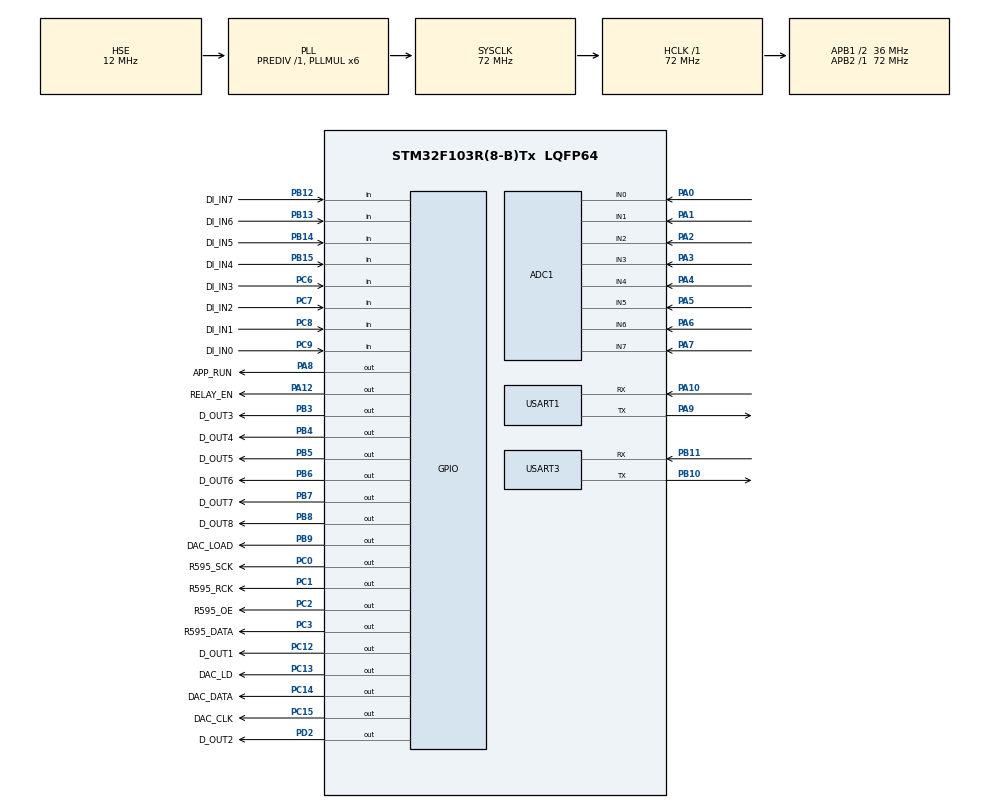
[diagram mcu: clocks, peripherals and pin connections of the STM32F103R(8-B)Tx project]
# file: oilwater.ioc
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ADC1.Channel-0\#ChannelRegularConversion=ADC_CHANNEL_0
ADC1.Channel-1\#ChannelRegularConversion=ADC_CHANNEL_1
ADC1.Channel-2\#ChannelRegularConversion=ADC_CHANNEL_2
ADC1.Channel-3\#ChannelRegularConversion=ADC_CHANNEL_3
ADC1.Channel-4\#ChannelRegularConversion=ADC_CHANNEL_4
ADC1.Channel-5\#ChannelRegularConversion=ADC_CHANNEL_5
ADC1.Channel-6\#ChannelRegularConversion=ADC_CHANNEL_6
ADC1.Channel-7\#ChannelRegularConversion=ADC_CHANNEL_7
ADC1.ContinuousConvMode=ENABLE
ADC1.DiscontinuousConvMode=DISABLE
ADC1.ExternalTrigConv=ADC_SOFTWARE_START
ADC1.NbrOfConversion=8
ADC1.NbrOfConversionFlag=1
ADC1.Rank-0\#ChannelRegularConversion=1
ADC1.Rank-1\#ChannelRegularConversion=2
ADC1.Rank-2\#ChannelRegularConversion=3
ADC1.Rank-3\#ChannelRegularConversion=4
ADC1.Rank-4\#ChannelRegularConversion=5
ADC1.Rank-5\#ChannelRegularConversion=6
ADC1.Rank-6\#ChannelRegularConversion=7
ADC1.Rank-7\#ChannelRegularConversion=8
ADC1.SamplingTime-0\#ChannelRegularConversion=ADC_SAMPLETIME_1CYCLE_5
ADC1.SamplingTime-1\#ChannelRegularConversion=ADC_SAMPLETIME_1CYCLE_5
ADC1.SamplingTime-2\#ChannelRegularConversion=ADC_SAMPLETIME_1CYCLE_5
ADC1.SamplingTime-3\#ChannelRegularConversion=ADC_SAMPLETIME_1CYCLE_5
ADC1.SamplingTime-4\#ChannelRegularConversion=ADC_SAMPLETIME_1CYCLE_5
ADC1.SamplingTime-5\#ChannelRegularConversion=ADC_SAMPLETIME_1CYCLE_5
ADC1.SamplingTime-6\#ChannelRegularConversion=ADC_SAMPLETIME_1CYCLE_5
ADC1.SamplingTime-7\#ChannelRegularConversion=ADC_SAMPLETIME_1CYCLE_5
ADC1.master=1
Dma.ADC1.0.Direction=DMA_PERIPH_TO_MEMORY
Dma.ADC1.0.Instance=DMA1_Channel1
Dma.ADC1.0.MemDataAlignment=DMA_MDATAALIGN_HALFWORD
Dma.ADC1.0.MemInc=DMA_MINC_ENABLE
Dma.ADC1.0.Mode=DMA_CIRCULAR
Dma.ADC1.0.PeriphDataAlignment=DMA_PDATAALIGN_HALFWORD
Dma.ADC1.0.PeriphInc=DMA_PINC_DISABLE
Dma.ADC1.0.Priority=DMA_PRIORITY_LOW
Dma.Request0=ADC1
Mcu.Family=STM32F1
Mcu.Name=STM32F103R(8-B)Tx
Mcu.Package=LQFP64
NVIC.ADC1_2_IRQn=true\:0\:0\:false\:false\:true\:true\:true
NVIC.DMA1_Channel1_IRQn=true\:0\:0\:false\:false\:true\:false\:true
NVIC.PriorityGroup=NVIC_PRIORITYGROUP_4
NVIC.USART1_IRQn=true\:0\:0\:false\:false\:true\:true\:true
NVIC.USART3_IRQn=true\:0\:0\:false\:false\:true\:true\:true
NVIC.WWDG_IRQn=true\:0\:0\:false\:false\:true\:true\:true
PA0-WKUP.Signal=ADCx_IN0
PA1.Signal=ADCx_IN1
PA10.Mode=Asynchronous
PA10.Signal=USART1_RX
PA12.GPIO_Label=RELAY_EN
PA12.Signal=GPIO_Output
PA13.Mode=Serial_Wire
PA13.Signal=SYS_JTMS-SWDIO
PA14.Mode=Serial_Wire
PA14.Signal=SYS_JTCK-SWCLK
PA2.Signal=ADCx_IN2
PA3.Signal=ADCx_IN3
PA4.Signal=ADCx_IN4
PA5.Signal=ADCx_IN5
PA6.Signal=ADCx_IN6
PA7.Signal=ADCx_IN7
PA8.GPIO_Label=APP_RUN
PA8.Signal=GPIO_Output
PA9.Mode=Asynchronous
PA9.Signal=USART1_TX
PB10.Mode=Asynchronous
PB10.Signal=USART3_TX
PB11.Mode=Asynchronous
PB11.Signal=USART3_RX
PB12.GPIO_Label=DI_IN7
PB12.Signal=GPIO_Input
PB13.GPIO_Label=DI_IN6
PB13.Signal=GPIO_Input
PB14.GPIO_Label=DI_IN5
PB14.Signal=GPIO_Input
PB15.GPIO_Label=DI_IN4
PB15.Signal=GPIO_Input
PB3.GPIO_Label=D_OUT3
PB3.Signal=GPIO_Output
PB4.GPIO_Label=D_OUT4
PB4.Signal=GPIO_Output
PB5.GPIO_Label=D_OUT5
PB5.Signal=GPIO_Output
PB6.GPIO_Label=D_OUT6
PB6.Signal=GPIO_Output
PB7.GPIO_Label=D_OUT7
PB7.Signal=GPIO_Output
PB8.GPIO_Label=D_OUT8
PB8.Signal=GPIO_Output
PB9.GPIO_Label=DAC_LOAD
PB9.Signal=GPIO_Output
PC0.GPIO_Label=R595_SCK
PC0.Signal=GPIO_Output
PC1.GPIO_Label=R595_RCK
PC1.Signal=GPIO_Output
PC12.GPIO_Label=D_OUT1
PC12.Signal=GPIO_Output
PC13-TAMPER-RTC.GPIO_Label=DAC_LD
PC13-TAMPER-RTC.Signal=GPIO_Output
PC14-OSC32_IN.GPIO_Label=DAC_DATA
PC14-OSC32_IN.Signal=GPIO_Output
PC15-OSC32_OUT.GPIO_Label=DAC_CLK
PC15-OSC32_OUT.Signal=GPIO_Output
PC2.GPIO_Label=R595_OE
PC2.Signal=GPIO_Output
PC3.GPIO_Label=R595_DATA
PC3.Signal=GPIO_Output
PC6.GPIO_Label=DI_IN3
PC6.Signal=GPIO_Input
PC7.GPIO_Label=DI_IN2
PC7.Signal=GPIO_Input
PC8.GPIO_Label=DI_IN1
PC8.Signal=GPIO_Input
PC9.GPIO_Label=DI_IN0
PC9.Signal=GPIO_Input
PD0-OSC_IN.Mode=HSE-External-Oscillator
PD0-OSC_IN.Signal=RCC_OSC_IN
PD1-OSC_OUT.Mode=HSE-External-Oscillator
PD1-OSC_OUT.Signal=RCC_OSC_OUT
PD2.GPIO_Label=D_OUT2
PD2.Signal=GPIO_Output
ProjectManager.HeapSize=0x200
ProjectManager.StackSize=0x400
ProjectManager.TargetToolchain=MDK-ARM V5
RCC.ADCPresc=RCC_ADCPCLK2_DIV6
RCC.AHBFreq_Value=72000000
RCC.APB1CLKDivider=RCC_HCLK_DIV2
RCC.APB1Freq_Value=36000000
RCC.APB1TimFreq_Value=72000000
RCC.APB2Freq_Value=72000000
RCC.APB2TimFreq_Value=72000000
RCC.HCLKFreq_Value=72000000
RCC.HSE_VALUE=12000000
RCC.PLLMUL=RCC_PLL_MUL6
RCC.PLLSourceVirtual=RCC_PLLSOURCE_HSE
RCC.SYSCLKFreq_VALUE=72000000
RCC.SYSCLKSource=RCC_SYSCLKSOURCE_PLLCLK
RCC.USBFreq_Value=72000000
SH.ADCx_IN0.0=ADC1_IN0,IN0
SH.ADCx_IN1.0=ADC1_IN1,IN1
SH.ADCx_IN2.0=ADC1_IN2,IN2
SH.ADCx_IN3.0=ADC1_IN3,IN3
SH.ADCx_IN4.0=ADC1_IN4,IN4
SH.ADCx_IN5.0=ADC1_IN5,IN5
SH.ADCx_IN6.0=ADC1_IN6,IN6
SH.ADCx_IN7.0=ADC1_IN7,IN7
USART1.VirtualMode=VM_ASYNC
USART3.VirtualMode=VM_ASYNC
VP_WWDG_VS_WWDG.Mode=WWDG_Activate
WWDG.Counter=127
WWDG.EWIMode=WWDG_EWI_ENABLE
WWDG.Prescaler=WWDG_PRESCALER_8
WWDG.Window=90
board=custom

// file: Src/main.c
/* USER CODE BEGIN Header */
/**
  ******************************************************************************
  * @file           : main.c
  * @brief          : Main program body
  ******************************************************************************
  * @attention
  *
  * <h2><center>&copy; Copyright (c) 2020 STMicroelectronics.
  * All rights reserved.</center></h2>
  *
  * This software component is licensed by ST under BSD 3-Clause license,
  * the "License"; You may not use this file except in compliance with the
  * License. You may obtain a copy of the License at:
  *                        opensource.org/licenses/BSD-3-Clause
  *
  ******************************************************************************
  */
/* USER CODE END Header */

#include "main.h"

/* USER CODE BEGIN Includes */
#include "platform.h"
#include "stdio.h"
/* USER CODE END Includes */

ADC_HandleTypeDef hadc1;
DMA_HandleTypeDef hdma_adc1;

UART_HandleTypeDef huart1;
UART_HandleTypeDef huart3;

WWDG_HandleTypeDef hwwdg;

void SystemClock_Config(void);
static void MX_GPIO_Init(void);
static void MX_DMA_Init(void);
static void MX_USART1_UART_Init(void);
static void MX_WWDG_Init(void);
static void MX_ADC1_Init(void);
static void MX_USART3_UART_Init(void);

int main(void)
{

  /* MCU Configuration--------------------------------------------------------*/

  /* Reset of all peripherals, Initializes the Flash interface and the Systick. */
  HAL_Init();

  /* Configure the system clock */
  SystemClock_Config();

  /* Initialize all configured peripherals */
  MX_GPIO_Init();
  MX_DMA_Init();
  MX_USART1_UART_Init();
  MX_WWDG_Init();
  MX_ADC1_Init();
  MX_USART3_UART_Init();
  /* USER CODE BEGIN 2 */

	static uint32_t tick = 0;
	HAL_GPIO_WritePin(RELAY_EN_GPIO_Port, RELAY_EN_Pin, GPIO_PIN_SET);   //使能继电器输出
	PLATFORM_Init();
	printf("system start");
  /* USER CODE END 2 */

  /* Infinite loop */
  while (1)
  {

    /* USER CODE BEGIN 3 */
		if(HAL_GetTick() - tick > 1000) {

			HAL_GPIO_TogglePin(APP_RUN_GPIO_Port, APP_RUN_Pin);
			tick = HAL_GetTick();
		}

		uartPoll();
		WWDG_Refresh();
  }
  /* USER CODE END 3 */
}

void SystemClock_Config(void)
{
  RCC_OscInitTypeDef RCC_OscInitStruct = {0};
  RCC_ClkInitTypeDef RCC_ClkInitStruct = {0};
  RCC_PeriphCLKInitTypeDef PeriphClkInit = {0};

  /** Initializes the CPU, AHB and APB busses clocks
  */
  RCC_OscInitStruct.OscillatorType = RCC_OSCILLATORTYPE_HSE;
  RCC_OscInitStruct.HSEState = RCC_HSE_ON;
  RCC_OscInitStruct.HSEPredivValue = RCC_HSE_PREDIV_DIV1;
  RCC_OscInitStruct.HSIState = RCC_HSI_ON;
  RCC_OscInitStruct.PLL.PLLState = RCC_PLL_ON;
  RCC_OscInitStruct.PLL.PLLSource = RCC_PLLSOURCE_HSE;
  RCC_OscInitStruct.PLL.PLLMUL = RCC_PLL_MUL6;
  if (HAL_RCC_OscConfig(&RCC_OscInitStruct) != HAL_OK)
  {
    Error_Handler();
  }
  /** Initializes the CPU, AHB and APB busses clocks
  */
  RCC_ClkInitStruct.ClockType = RCC_CLOCKTYPE_HCLK|RCC_CLOCKTYPE_SYSCLK
                              |RCC_CLOCKTYPE_PCLK1|RCC_CLOCKTYPE_PCLK2;
  RCC_ClkInitStruct.SYSCLKSource = RCC_SYSCLKSOURCE_PLLCLK;
  RCC_ClkInitStruct.AHBCLKDivider = RCC_SYSCLK_DIV1;
  RCC_ClkInitStruct.APB1CLKDivider = RCC_HCLK_DIV2;
  RCC_ClkInitStruct.APB2CLKDivider = RCC_HCLK_DIV1;

  if (HAL_RCC_ClockConfig(&RCC_ClkInitStruct, FLASH_LATENCY_2) != HAL_OK)
  {
    Error_Handler();
  }
  PeriphClkInit.PeriphClockSelection = RCC_PERIPHCLK_ADC;
  PeriphClkInit.AdcClockSelection = RCC_ADCPCLK2_DIV6;
  if (HAL_RCCEx_PeriphCLKConfig(&PeriphClkInit) != HAL_OK)
  {
    Error_Handler();
  }
}

static void MX_ADC1_Init(void)
{

  ADC_ChannelConfTypeDef sConfig = {0};

  /** Common config
  */
  hadc1.Instance = ADC1;
  hadc1.Init.ScanConvMode = ADC_SCAN_ENABLE;
  hadc1.Init.ContinuousConvMode = ENABLE;
  hadc1.Init.DiscontinuousConvMode = DISABLE;
  hadc1.Init.ExternalTrigConv = ADC_SOFTWARE_START;
  hadc1.Init.DataAlign = ADC_DATAALIGN_RIGHT;
  hadc1.Init.NbrOfConversion = 8;
  if (HAL_ADC_Init(&hadc1) != HAL_OK)
  {
    Error_Handler();
  }
  /** Configure Regular Channel
  */
  sConfig.Channel = ADC_CHANNEL_0;
  sConfig.Rank = ADC_REGULAR_RANK_1;
  sConfig.SamplingTime = ADC_SAMPLETIME_1CYCLE_5;
  if (HAL_ADC_ConfigChannel(&hadc1, &sConfig) != HAL_OK)
  {
    Error_Handler();
  }
  /** Configure Regular Channel
  */
  sConfig.Channel = ADC_CHANNEL_1;
  sConfig.Rank = ADC_REGULAR_RANK_2;
  if (HAL_ADC_ConfigChannel(&hadc1, &sConfig) != HAL_OK)
  {
    Error_Handler();
  }
  /** Configure Regular Channel
  */
  sConfig.Channel = ADC_CHANNEL_2;
  sConfig.Rank = ADC_REGULAR_RANK_3;
  if (HAL_ADC_ConfigChannel(&hadc1, &sConfig) != HAL_OK)
  {
    Error_Handler();
  }
  /** Configure Regular Channel
  */
  sConfig.Channel = ADC_CHANNEL_3;
  sConfig.Rank = ADC_REGULAR_RANK_4;
  if (HAL_ADC_ConfigChannel(&hadc1, &sConfig) != HAL_OK)
  {
    Error_Handler();
  }
  /** Configure Regular Channel
  */
  sConfig.Channel = ADC_CHANNEL_4;
  sConfig.Rank = ADC_REGULAR_RANK_5;
  if (HAL_ADC_ConfigChannel(&hadc1, &sConfig) != HAL_OK)
  {
    Error_Handler();
  }
  /** Configure Regular Channel
  */
  sConfig.Channel = ADC_CHANNEL_5;
  sConfig.Rank = ADC_REGULAR_RANK_6;
  if (HAL_ADC_ConfigChannel(&hadc1, &sConfig) != HAL_OK)
  {
    Error_Handler();
  }
  /** Configure Regular Channel
  */
  sConfig.Channel = ADC_CHANNEL_6;
  sConfig.Rank = ADC_REGULAR_RANK_7;
  if (HAL_ADC_ConfigChannel(&hadc1, &sConfig) != HAL_OK)
  {
    Error_Handler();
  }
  /** Configure Regular Channel
  */
  sConfig.Channel = ADC_CHANNEL_7;
  sConfig.Rank = ADC_REGULAR_RANK_8;
  if (HAL_ADC_ConfigChannel(&hadc1, &sConfig) != HAL_OK)
  {
    Error_Handler();
  }

}

static void MX_USART1_UART_Init(void)
{

  huart1.Instance = USART1;
  huart1.Init.BaudRate = 115200;
  huart1.Init.WordLength = UART_WORDLENGTH_8B;
  huart1.Init.StopBits = UART_STOPBITS_1;
  huart1.Init.Parity = UART_PARITY_NONE;
  huart1.Init.Mode = UART_MODE_TX_RX;
  huart1.Init.HwFlowCtl = UART_HWCONTROL_NONE;
  huart1.Init.OverSampling = UART_OVERSAMPLING_16;
  if (HAL_UART_Init(&huart1) != HAL_OK)
  {
    Error_Handler();
  }

}

static void MX_USART3_UART_Init(void)
{

  huart3.Instance = USART3;
  huart3.Init.BaudRate = 115200;
  huart3.Init.WordLength = UART_WORDLENGTH_8B;
  huart3.Init.StopBits = UART_STOPBITS_1;
  huart3.Init.Parity = UART_PARITY_NONE;
  huart3.Init.Mode = UART_MODE_TX_RX;
  huart3.Init.HwFlowCtl = UART_HWCONTROL_NONE;
  huart3.Init.OverSampling = UART_OVERSAMPLING_16;
  if (HAL_UART_Init(&huart3) != HAL_OK)
  {
    Error_Handler();
  }

}

static void MX_WWDG_Init(void)
{

  hwwdg.Instance = WWDG;
  hwwdg.Init.Prescaler = WWDG_PRESCALER_8;
  hwwdg.Init.Window = 90;
  hwwdg.Init.Counter = 127;
  hwwdg.Init.EWIMode = WWDG_EWI_ENABLE;
  if (HAL_WWDG_Init(&hwwdg) != HAL_OK)
  {
    Error_Handler();
  }

}

static void MX_DMA_Init(void)
{

  /* DMA controller clock enable */
  __HAL_RCC_DMA1_CLK_ENABLE();

  /* DMA interrupt init */
  /* DMA1_Channel1_IRQn interrupt configuration */
  HAL_NVIC_SetPriority(DMA1_Channel1_IRQn, 0, 0);
  HAL_NVIC_EnableIRQ(DMA1_Channel1_IRQn);

}

static void MX_GPIO_Init(void)
{
  GPIO_InitTypeDef GPIO_InitStruct = {0};

  /* GPIO Ports Clock Enable */
  __HAL_RCC_GPIOC_CLK_ENABLE();
  __HAL_RCC_GPIOD_CLK_ENABLE();
  __HAL_RCC_GPIOA_CLK_ENABLE();
  __HAL_RCC_GPIOB_CLK_ENABLE();

  /*Configure GPIO pin Output Level */
  HAL_GPIO_WritePin(GPIOC, DAC_LD_Pin|DAC_DATA_Pin|DAC_CLK_Pin|R595_SCK_Pin
                          |R595_RCK_Pin|R595_OE_Pin|R595_DATA_Pin|D_OUT1_Pin, GPIO_PIN_RESET);

  /*Configure GPIO pin Output Level */
  HAL_GPIO_WritePin(GPIOA, APP_RUN_Pin|RELAY_EN_Pin, GPIO_PIN_RESET);

  /*Configure GPIO pin Output Level */
  HAL_GPIO_WritePin(D_OUT2_GPIO_Port, D_OUT2_Pin, GPIO_PIN_RESET);

  /*Configure GPIO pin Output Level */
  HAL_GPIO_WritePin(GPIOB, D_OUT3_Pin|D_OUT4_Pin|D_OUT5_Pin|D_OUT6_Pin
                          |D_OUT7_Pin|D_OUT8_Pin|DAC_LOAD_Pin, GPIO_PIN_RESET);

  /*Configure GPIO pins : DAC_LD_Pin DAC_DATA_Pin DAC_CLK_Pin R595_SCK_Pin
                           R595_RCK_Pin R595_OE_Pin R595_DATA_Pin D_OUT1_Pin */
  GPIO_InitStruct.Pin = DAC_LD_Pin|DAC_DATA_Pin|DAC_CLK_Pin|R595_SCK_Pin
                          |R595_RCK_Pin|R595_OE_Pin|R595_DATA_Pin|D_OUT1_Pin;
  GPIO_InitStruct.Mode = GPIO_MODE_OUTPUT_PP;
  GPIO_InitStruct.Pull = GPIO_NOPULL;
  GPIO_InitStruct.Speed = GPIO_SPEED_FREQ_LOW;
  HAL_GPIO_Init(GPIOC, &GPIO_InitStruct);

  /*Configure GPIO pins : DI_IN7_Pin DI_IN6_Pin DI_IN5_Pin DI_IN4_Pin */
  GPIO_InitStruct.Pin = DI_IN7_Pin|DI_IN6_Pin|DI_IN5_Pin|DI_IN4_Pin;
  GPIO_InitStruct.Mode = GPIO_MODE_INPUT;
  GPIO_InitStruct.Pull = GPIO_NOPULL;
  HAL_GPIO_Init(GPIOB, &GPIO_InitStruct);

  /*Configure GPIO pins : DI_IN3_Pin DI_IN2_Pin DI_IN1_Pin DI_IN0_Pin */
  GPIO_InitStruct.Pin = DI_IN3_Pin|DI_IN2_Pin|DI_IN1_Pin|DI_IN0_Pin;
  GPIO_InitStruct.Mode = GPIO_MODE_INPUT;
  GPIO_InitStruct.Pull = GPIO_NOPULL;
  HAL_GPIO_Init(GPIOC, &GPIO_InitStruct);

  /*Configure GPIO pins : APP_RUN_Pin RELAY_EN_Pin */
  GPIO_InitStruct.Pin = APP_RUN_Pin|RELAY_EN_Pin;
  GPIO_InitStruct.Mode = GPIO_MODE_OUTPUT_PP;
  GPIO_InitStruct.Pull = GPIO_NOPULL;
  GPIO_InitStruct.Speed = GPIO_SPEED_FREQ_LOW;
  HAL_GPIO_Init(GPIOA, &GPIO_InitStruct);

  /*Configure GPIO pin : D_OUT2_Pin */
  GPIO_InitStruct.Pin = D_OUT2_Pin;
  GPIO_InitStruct.Mode = GPIO_MODE_OUTPUT_PP;
  GPIO_InitStruct.Pull = GPIO_NOPULL;
  GPIO_InitStruct.Speed = GPIO_SPEED_FREQ_LOW;
  HAL_GPIO_Init(D_OUT2_GPIO_Port, &GPIO_InitStruct);

  /*Configure GPIO pins : D_OUT3_Pin D_OUT4_Pin D_OUT5_Pin D_OUT6_Pin
                           D_OUT7_Pin D_OUT8_Pin DAC_LOAD_Pin */
  GPIO_InitStruct.Pin = D_OUT3_Pin|D_OUT4_Pin|D_OUT5_Pin|D_OUT6_Pin
                          |D_OUT7_Pin|D_OUT8_Pin|DAC_LOAD_Pin;
  GPIO_InitStruct.Mode = GPIO_MODE_OUTPUT_PP;
  GPIO_InitStruct.Pull = GPIO_NOPULL;
  GPIO_InitStruct.Speed = GPIO_SPEED_FREQ_LOW;
  HAL_GPIO_Init(GPIOB, &GPIO_InitStruct);

}

void Error_Handler(void)
{
}

/************************ (C) COPYRIGHT STMicroelectronics *****END OF FILE****/
